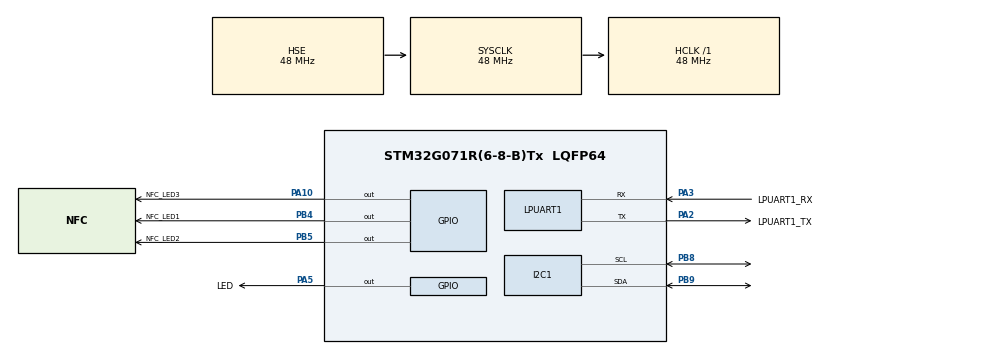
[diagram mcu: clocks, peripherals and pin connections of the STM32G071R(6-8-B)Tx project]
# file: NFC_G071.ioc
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I2C1.Timing=0x20303E5D
Mcu.Family=STM32G0
Mcu.Name=STM32G071R(6-8-B)Tx
Mcu.Package=LQFP64
PA10.GPIO_Label=NFC_LED3
PA10.Signal=GPIO_Output
PA13.GPIO_Label=TMS
PA13.Mode=Serial_Wire
PA13.Signal=SYS_SWDIO
PA14-BOOT0.GPIO_Label=TCK
PA14-BOOT0.Mode=Serial_Wire
PA14-BOOT0.Signal=SYS_SWCLK
PA2.GPIO_Label=LPUART1_TX
PA2.Mode=Asynchronous
PA2.Signal=LPUART1_TX
PA3.GPIO_Label=LPUART1_RX
PA3.Mode=Asynchronous
PA3.Signal=LPUART1_RX
PA5.GPIO_Label=LED
PA5.Signal=GPIO_Output
PB4.GPIO_Label=NFC_LED1
PB4.Signal=GPIO_Output
PB5.GPIO_Label=NFC_LED2
PB5.Signal=GPIO_Output
PB8.GPIO_Speed=GPIO_SPEED_FREQ_VERY_HIGH
PB8.Mode=I2C
PB8.Signal=I2C1_SCL
PB9.GPIO_Speed=GPIO_SPEED_FREQ_VERY_HIGH
PB9.Mode=I2C
PB9.Signal=I2C1_SDA
PC13.Mode=SYS_WakeUp1
PC13.Signal=SYS_WKUP2
PC14-OSC32_IN\ (PC14).Mode=LSE-External-Oscillator
PC14-OSC32_IN\ (PC14).Signal=RCC_OSC32_IN
PC15-OSC32_OUT\ (PC15).Mode=LSE-External-Oscillator
PC15-OSC32_OUT\ (PC15).Signal=RCC_OSC32_OUT
PF0-OSC_IN\ (PF0).GPIO_Label=MCO
PF0-OSC_IN\ (PF0).Mode=HSE-External-Clock-Source
PF0-OSC_IN\ (PF0).Signal=RCC_OSC_IN
ProjectManager.HeapSize=0x200
ProjectManager.StackSize=0x400
ProjectManager.TargetToolchain=SW4STM32
RCC.ADCFreq_Value=48000000
RCC.AHBFreq_Value=48000000
RCC.CortexFreq_Value=48000000
RCC.EXTERNAL_CLOCK_VALUE=12288000
RCC.HCLKFreq_Value=48000000
RCC.HSE_VALUE=48000000
RCC.HSI_VALUE=16000000
RCC.SYSCLKFreq_VALUE=48000000
RCC.SYSCLKSource=RCC_SYSCLKSOURCE_HSE
RCC.VCOOutputFreq_Value=128000000
board=NUCLEO-G071RB

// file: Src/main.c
/* USER CODE BEGIN Header */
/**
  ******************************************************************************
  * @file           : main.c
  * @brief          : Main program body
  ******************************************************************************
  ** This notice applies to any and all portions of this file
  * that are not between comment pairs USER CODE BEGIN and
  * USER CODE END. Other portions of this file, whether
  * inserted by the user or by software development tools
  * are owned by their respective copyright owners.
  *
  * COPYRIGHT(c) 2019 STMicroelectronics
  *
  * Redistribution and use in source and binary forms, with or without modification,
  * are permitted provided that the following conditions are met:
  *   1. Redistributions of source code must retain the above copyright notice,
  *      this list of conditions and the following disclaimer.
  *   2. Redistributions in binary form must reproduce the above copyright notice,
  *      this list of conditions and the following disclaimer in the documentation
  *      and/or other materials provided with the distribution.
  *   3. Neither the name of STMicroelectronics nor the names of its contributors
  *      may be used to endorse or promote products derived from this software
  *      without specific prior written permission.
  *
  * THIS SOFTWARE IS PROVIDED BY THE COPYRIGHT HOLDERS AND CONTRIBUTORS "AS IS"
  * AND ANY EXPRESS OR IMPLIED WARRANTIES, INCLUDING, BUT NOT LIMITED TO, THE
  * IMPLIED WARRANTIES OF MERCHANTABILITY AND FITNESS FOR A PARTICULAR PURPOSE ARE
  * DISCLAIMED. IN NO EVENT SHALL THE COPYRIGHT HOLDER OR CONTRIBUTORS BE LIABLE
  * FOR ANY DIRECT, INDIRECT, INCIDENTAL, SPECIAL, EXEMPLARY, OR CONSEQUENTIAL
  * DAMAGES (INCLUDING, BUT NOT LIMITED TO, PROCUREMENT OF SUBSTITUTE GOODS OR
  * SERVICES; LOSS OF USE, DATA, OR PROFITS; OR BUSINESS INTERRUPTION) HOWEVER
  * CAUSED AND ON ANY THEORY OF LIABILITY, WHETHER IN CONTRACT, STRICT LIABILITY,
  * OR TORT (INCLUDING NEGLIGENCE OR OTHERWISE) ARISING IN ANY WAY OUT OF THE USE
  * OF THIS SOFTWARE, EVEN IF ADVISED OF THE POSSIBILITY OF SUCH DAMAGE.
  *
  ******************************************************************************
  */
/* USER CODE END Header */

#include "main.h"

/* USER CODE BEGIN Includes */
#include "stdint.h"
#include "nfc.h"
/* USER CODE END Includes */

I2C_HandleTypeDef hi2c1;

UART_HandleTypeDef hlpuart1;

void SystemClock_Config(void);
static void MX_GPIO_Init(void);
static void MX_LPUART1_UART_Init(void);
static void MX_I2C1_Init(void);

int main(void)
{

  /* MCU Configuration--------------------------------------------------------*/

  /* Reset of all peripherals, Initializes the Flash interface and the Systick. */
  HAL_Init();

  /* Configure the system clock */
  SystemClock_Config();

  /* Initialize all configured peripherals */
  MX_GPIO_Init();
  MX_LPUART1_UART_Init();
  MX_I2C1_Init();
  /* USER CODE BEGIN 2 */
  unsigned char buffer[6];
  buffer[0]= 0x11;
  buffer[1]= 0x22;
  buffer[2]= 0x33;
  buffer[3]= 0x44;
  buffer[4]= 0x55;
  buffer[5]= 0x66;

  initNFC(&hi2c1, (NFC_UserMemory));
  //HAL_I2C_Master_Transmit(&hi2c1, (NFC_UserMemory), buffer, 5,10);
  HAL_I2C_Mem_Write(&hi2c1,NFC_UserMemory,0x1A,0x04,buffer,5,50);
  /* USER CODE END 2 */

  /* Infinite loop */
  while (1)
  {

    /* USER CODE BEGIN 3 */
	  HAL_Delay(50);
	  //HAL_GPIO_TogglePin(LED_GPIO_Port,LED_Pin);
  }
  /* USER CODE END 3 */
}

void SystemClock_Config(void)
{
  RCC_OscInitTypeDef RCC_OscInitStruct = {0};
  RCC_ClkInitTypeDef RCC_ClkInitStruct = {0};
  RCC_PeriphCLKInitTypeDef PeriphClkInit = {0};

  /**Configure the main internal regulator output voltage
  */
  HAL_PWREx_ControlVoltageScaling(PWR_REGULATOR_VOLTAGE_SCALE1);
  /**Initializes the CPU, AHB and APB busses clocks
  */
  RCC_OscInitStruct.OscillatorType = RCC_OSCILLATORTYPE_HSE;
  RCC_OscInitStruct.HSEState = RCC_HSE_BYPASS;
  RCC_OscInitStruct.PLL.PLLState = RCC_PLL_NONE;
  if (HAL_RCC_OscConfig(&RCC_OscInitStruct) != HAL_OK)
  {
    Error_Handler();
  }
  /**Initializes the CPU, AHB and APB busses clocks
  */
  RCC_ClkInitStruct.ClockType = RCC_CLOCKTYPE_HCLK|RCC_CLOCKTYPE_SYSCLK
                              |RCC_CLOCKTYPE_PCLK1;
  RCC_ClkInitStruct.SYSCLKSource = RCC_SYSCLKSOURCE_HSE;
  RCC_ClkInitStruct.AHBCLKDivider = RCC_SYSCLK_DIV1;
  RCC_ClkInitStruct.APB1CLKDivider = RCC_HCLK_DIV1;

  if (HAL_RCC_ClockConfig(&RCC_ClkInitStruct, FLASH_LATENCY_1) != HAL_OK)
  {
    Error_Handler();
  }
  /**Initializes the peripherals clocks
  */
  PeriphClkInit.PeriphClockSelection = RCC_PERIPHCLK_LPUART1|RCC_PERIPHCLK_I2C1;
  PeriphClkInit.Lpuart1ClockSelection = RCC_LPUART1CLKSOURCE_PCLK1;
  PeriphClkInit.I2c1ClockSelection = RCC_I2C1CLKSOURCE_PCLK1;
  if (HAL_RCCEx_PeriphCLKConfig(&PeriphClkInit) != HAL_OK)
  {
    Error_Handler();
  }
}

static void MX_I2C1_Init(void)
{

  hi2c1.Instance = I2C1;
  hi2c1.Init.Timing = 0x20303E5D;
  hi2c1.Init.OwnAddress1 = 0;
  hi2c1.Init.AddressingMode = I2C_ADDRESSINGMODE_7BIT;
  hi2c1.Init.DualAddressMode = I2C_DUALADDRESS_DISABLE;
  hi2c1.Init.OwnAddress2 = 0;
  hi2c1.Init.OwnAddress2Masks = I2C_OA2_NOMASK;
  hi2c1.Init.GeneralCallMode = I2C_GENERALCALL_DISABLE;
  hi2c1.Init.NoStretchMode = I2C_NOSTRETCH_DISABLE;
  if (HAL_I2C_Init(&hi2c1) != HAL_OK)
  {
    Error_Handler();
  }
  /**Configure Analogue filter
  */
  if (HAL_I2CEx_ConfigAnalogFilter(&hi2c1, I2C_ANALOGFILTER_ENABLE) != HAL_OK)
  {
    Error_Handler();
  }
  /**Configure Digital filter
  */
  if (HAL_I2CEx_ConfigDigitalFilter(&hi2c1, 0) != HAL_OK)
  {
    Error_Handler();
  }

}

static void MX_LPUART1_UART_Init(void)
{

  hlpuart1.Instance = LPUART1;
  hlpuart1.Init.BaudRate = 209700;
  hlpuart1.Init.WordLength = UART_WORDLENGTH_7B;
  hlpuart1.Init.StopBits = UART_STOPBITS_1;
  hlpuart1.Init.Parity = UART_PARITY_NONE;
  hlpuart1.Init.Mode = UART_MODE_TX_RX;
  hlpuart1.Init.HwFlowCtl = UART_HWCONTROL_NONE;
  hlpuart1.Init.OneBitSampling = UART_ONE_BIT_SAMPLE_DISABLE;
  hlpuart1.Init.ClockPrescaler = UART_PRESCALER_DIV1;
  hlpuart1.AdvancedInit.AdvFeatureInit = UART_ADVFEATURE_NO_INIT;
  hlpuart1.FifoMode = UART_FIFOMODE_DISABLE;
  if (HAL_UART_Init(&hlpuart1) != HAL_OK)
  {
    Error_Handler();
  }
  if (HAL_UARTEx_SetTxFifoThreshold(&hlpuart1, UART_TXFIFO_THRESHOLD_1_8) != HAL_OK)
  {
    Error_Handler();
  }
  if (HAL_UARTEx_SetRxFifoThreshold(&hlpuart1, UART_RXFIFO_THRESHOLD_1_8) != HAL_OK)
  {
    Error_Handler();
  }
  if (HAL_UARTEx_DisableFifoMode(&hlpuart1) != HAL_OK)
  {
    Error_Handler();
  }

}

static void MX_GPIO_Init(void)
{
  GPIO_InitTypeDef GPIO_InitStruct = {0};

  /* GPIO Ports Clock Enable */
  __HAL_RCC_GPIOC_CLK_ENABLE();
  __HAL_RCC_GPIOF_CLK_ENABLE();
  __HAL_RCC_GPIOA_CLK_ENABLE();
  __HAL_RCC_GPIOB_CLK_ENABLE();

  /*Configure GPIO pin Output Level */
  HAL_GPIO_WritePin(GPIOA, LED_Pin|NFC_LED3_Pin, GPIO_PIN_RESET);

  /*Configure GPIO pin Output Level */
  HAL_GPIO_WritePin(GPIOB, NFC_LED1_Pin|NFC_LED2_Pin, GPIO_PIN_RESET);

  /*Configure GPIO pins : LED_Pin NFC_LED3_Pin */
  GPIO_InitStruct.Pin = LED_Pin|NFC_LED3_Pin;
  GPIO_InitStruct.Mode = GPIO_MODE_OUTPUT_PP;
  GPIO_InitStruct.Pull = GPIO_NOPULL;
  GPIO_InitStruct.Speed = GPIO_SPEED_FREQ_LOW;
  HAL_GPIO_Init(GPIOA, &GPIO_InitStruct);

  /*Configure GPIO pins : NFC_LED1_Pin NFC_LED2_Pin */
  GPIO_InitStruct.Pin = NFC_LED1_Pin|NFC_LED2_Pin;
  GPIO_InitStruct.Mode = GPIO_MODE_OUTPUT_PP;
  GPIO_InitStruct.Pull = GPIO_NOPULL;
  GPIO_InitStruct.Speed = GPIO_SPEED_FREQ_LOW;
  HAL_GPIO_Init(GPIOB, &GPIO_InitStruct);

}

void Error_Handler(void)
{
}

/************************ (C) COPYRIGHT STMicroelectronics *****END OF FILE****/
